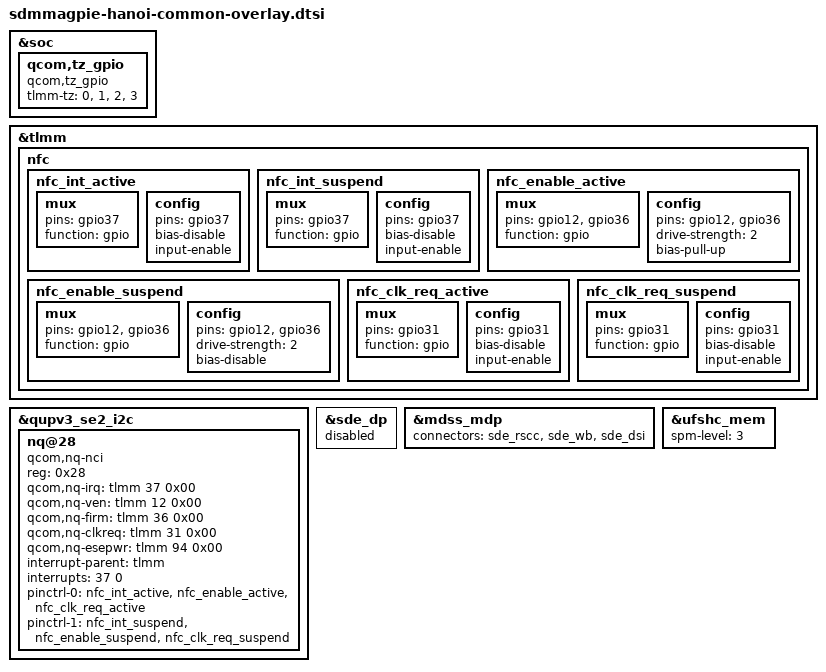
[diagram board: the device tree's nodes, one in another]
/* Copyright (c) 2018, The Linux Foundation. All rights reserved.
 *
 * This program is free software; you can redistribute it and/or modify
 * it under the terms of the GNU General Public License version 2 and
 * only version 2 as published by the Free Software Foundation.
 *
 * This program is distributed in the hope that it will be useful,
 * but WITHOUT ANY WARRANTY; without even the implied warranty of
 * MERCHANTABILITY or FITNESS FOR A PARTICULAR PURPOSE.  See the
 * GNU General Public License for more details.
 */

#include "sdmmagpie-moto-common-overlay.dtsi"
#include "sdmmagpie-audio-overlay.dtsi"
#include "sdmmagpie-hario-fps-overlay.dtsi"
#include "hanoi-panel.dtsi"
#include "sdmmagpie-camera-sensor-mot-hanoi-overlay.dtsi"
#include "hanoi_battery_thermal_overlay.dtsi"
#include "sdmmagpie-hanoi-sensor-overlay.dtsi"
#include "sdmmagpie-hanoi-touchscreen.dtsi"
#include "sdmmagpie-hanoi-audio-overlay.dtsi"

&soc {
	qcom,tz_gpio {
		compatible = "qcom,tz_gpio";
		tlmm-tz = <0>,
			<1>,
			<2>,
			<3>;
	};
};


&tlmm{
	nfc {
		nfc_int_active: nfc_int_active {
			/* active state */
			mux {
				/* GPIO37 NFC Read Interrupt */
				pins = "gpio37";
				function = "gpio";
			};

			config {
				pins = "gpio37";
				bias-disable;
				input-enable;
			};
		};

		nfc_int_suspend: nfc_int_suspend {
			/* sleep state */
			mux {
				/* GPIO 37 NFC Read Interrupt */
				pins = "gpio37";
				function = "gpio";
			};

			config {
				pins = "gpio37";
				bias-disable;
				input-enable;
			};
		};

		nfc_enable_active: nfc_enable_active {
			/* active state */
			mux {
				/* 12: Enable 36: Firmware */
				pins = "gpio12", "gpio36";
				function = "gpio";
			};

			config {
				pins = "gpio12", "gpio36";
				drive-strength = <2>; /* 2 MA */
				bias-pull-up;
			};
		};

		nfc_enable_suspend: nfc_enable_suspend {
			/* sleep state */
			mux {
				/* 12: Enable 36: Firmware */
				pins = "gpio12", "gpio36";
				function = "gpio";
			};

			config {
				pins = "gpio12", "gpio36";
				drive-strength = <2>; /* 2 MA */
				bias-disable;
			};
		};

		nfc_clk_req_active: nfc_clk_req_active {
			/* active state */
			mux {
				/* 31: NFC CLOCK REQUEST */
				pins = "gpio31";
				function = "gpio";
			};

			config {
				pins = "gpio31";
				bias-disable;
				input-enable;
			};
		};

		nfc_clk_req_suspend: nfc_clk_req_suspend {
			/* sleep state */
			mux {
				/* 31: NFC CLOCK REQUEST */
				pins = "gpio31";
				function = "gpio";
			};

			config {
				pins = "gpio31";
				bias-disable;
				input-enable;
			};
		};
	};
};

&qupv3_se2_i2c {
	status = "ok";
	nq@28 {
		compatible = "qcom,nq-nci";
		reg = <0x28>;
		qcom,nq-irq = <&tlmm 37 0x00>;
		qcom,nq-ven = <&tlmm 12 0x00>;
		qcom,nq-firm = <&tlmm 36 0x00>;
		qcom,nq-clkreq = <&tlmm 31 0x00>;
		qcom,nq-esepwr = <&tlmm 94 0x00>;
		interrupt-parent = <&tlmm>;
		interrupts = <37 0>;
		interrupt-names = "nfc_irq";
		pinctrl-names = "nfc_active", "nfc_suspend";
		pinctrl-0 = <&nfc_int_active &nfc_enable_active
				&nfc_clk_req_active>;
		pinctrl-1 = <&nfc_int_suspend &nfc_enable_suspend
				&nfc_clk_req_suspend>;
	};
};

&sde_dp {
	status = "disabled";
};


&mdss_mdp {
	connectors = <&sde_rscc &sde_wb &sde_dsi>;
};

&ufshc_mem {
        spm-level = <3>;
};
